# StarFive VisionFive 2 v1.2A register map
File version: 0.1
Registers are 32-bit, read-write, reset 0x0 unless marked. A register's access mark holds for its fields unless they carry their own. Offsets are from the block's base; [hi:lo] are bit positions; {n}, {i} and the like mark numbered series; 'fields as' and 'values as' point back to an identical list.

## stg_syscon — From starfive,jh7110-stg-syscon, peripheral generator
Base 0x10240000
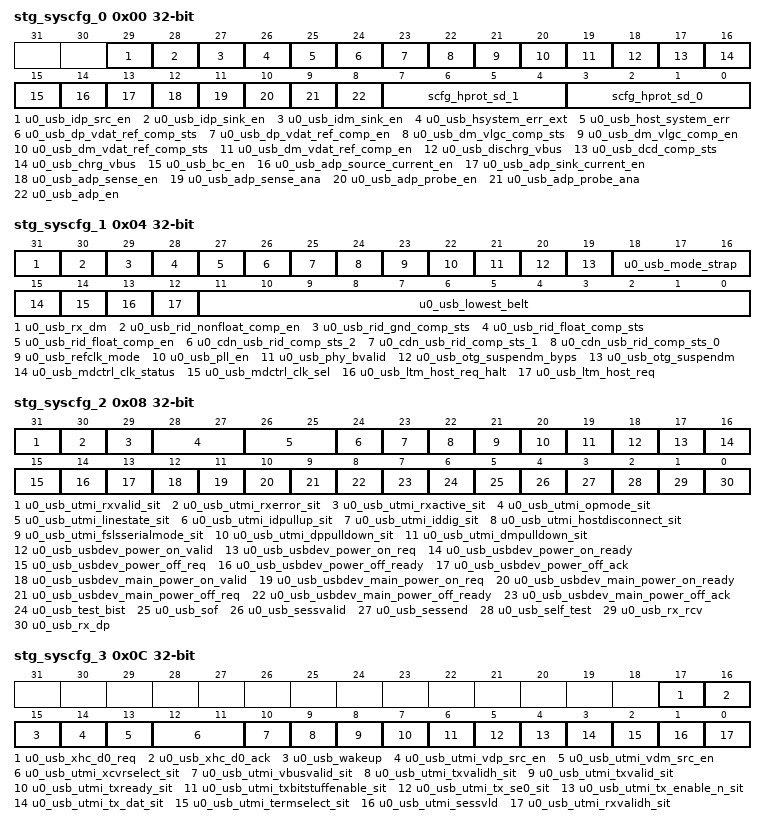
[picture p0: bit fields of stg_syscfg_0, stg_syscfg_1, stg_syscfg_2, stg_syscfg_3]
0x00 stg_syscfg_0 — STG SYCONSAIF SYSCFG 0
  [29] u0_usb_idp_src_en ro, [28] u0_usb_idp_sink_en ro, [27] u0_usb_idm_sink_en ro, [26] u0_usb_hsystem_err_ext ro, [25] u0_usb_host_system_err, [24] u0_usb_dp_vdat_ref_comp_sts, [23] u0_usb_dp_vdat_ref_comp_en ro, [22] u0_usb_dm_vlgc_comp_sts, [21] u0_usb_dm_vlgc_comp_en ro, [20] u0_usb_dm_vdat_ref_comp_sts, [19] u0_usb_dm_vdat_ref_comp_en ro, [18] u0_usb_dischrg_vbus, [17] u0_usb_dcd_comp_sts, [16] u0_usb_chrg_vbus, [15] u0_usb_bc_en ro, [14] u0_usb_adp_source_current_en ro, [13] u0_usb_adp_sink_current_en ro, [12] u0_usb_adp_sense_en ro, [11] u0_usb_adp_sense_ana, [10] u0_usb_adp_probe_en ro, [9] u0_usb_adp_probe_ana, [8] u0_usb_adp_en ro, [7:4] scfg_hprot_sd_1, [3:0] scfg_hprot_sd_0
0x04 stg_syscfg_1 — STG SYSCONSAIF SYSCFG 4
  [31] u0_usb_rx_dm ro
  [30] u0_usb_rid_nonfloat_comp_en ro
  [29] u0_usb_rid_gnd_comp_sts
  [28] u0_usb_rid_float_comp_sts
  [27] u0_usb_rid_float_comp_en ro
  [26] u0_cdn_usb_rid_comp_sts_2
  [25] u0_cdn_usb_rid_comp_sts_1
  [24] u0_cdn_usb_rid_comp_sts_0
  [23] u0_usb_refclk_mode
  [22] u0_usb_pll_en
  [21] u0_usb_phy_bvalid ro
  [20] u0_usb_otg_suspendm_byps
  [19] u0_usb_otg_suspendm
  [18:16] u0_usb_mode_strap — Can onlly be changed when pwrup_rst_n is low
  [15] u0_usb_mdctrl_clk_status ro
  [14] u0_usb_mdctrl_clk_sel
  [13] u0_usb_ltm_host_req_halt — LTM interface to software
  [12] u0_usb_ltm_host_req ro — LTM interface to software
  [11:0] u0_usb_lowest_belt ro — LTM interface to software
0x08 stg_syscfg_2 — STG SYSCONSAIF SYSCFG 8
  [31] u0_usb_utmi_rxvalid_sit ro
  [30] u0_usb_utmi_rxerror_sit ro
  [29] u0_usb_utmi_rxactive_sit ro
  [28:27] u0_usb_utmi_opmode_sit
  [26:25] u0_usb_utmi_linestate_sit ro
  [24] u0_usb_utmi_idpullup_sit
  [23] u0_usb_utmi_iddig_sit ro
  [22] u0_usb_utmi_hostdisconnect_sit ro
  [21] u0_usb_utmi_fslsserialmode_sit
  [20] u0_usb_utmi_dppulldown_sit
  [19] u0_usb_utmi_dmpulldown_sit
  [18] u0_usb_usbdev_power_on_valid
  [17] u0_usb_usbdev_power_on_req ro
  [16] u0_usb_usbdev_power_on_ready ro
  [15] u0_usb_usbdev_power_off_req
  [14] u0_usb_usbdev_power_off_ready ro
  [13] u0_usb_usbdev_power_off_ack ro
  [12] u0_usb_usbdev_main_power_on_valid
  [11] u0_usb_usbdev_main_power_on_req ro
  [10] u0_usb_usbdev_main_power_on_ready ro
  [9] u0_usb_usbdev_main_power_off_req
  [8] u0_usb_usbdev_main_power_off_ready ro
  [7] u0_usb_usbdev_main_power_off_ack ro
  [6] u0_usb_test_bist ro — For software bist_test
  [5] u0_usb_sof ro
  [4] u0_usb_sessvalid ro
  [3] u0_usb_sessend ro
  [2] u0_usb_self_test — For software bist_test
  [1] u0_usb_rx_rcv ro
  [0] u0_usb_rx_dp ro
0x0C stg_syscfg_3 — STG SYSCONSAIF SYSCFG 12
  [17] u0_usb_xhc_d0_req, [16] u0_usb_xhc_d0_ack ro, [15] u0_usb_wakeup, [14] u0_usb_utmi_vdp_src_en ro, [13] u0_usb_utmi_vdm_src_en ro, [12:11] u0_usb_utmi_xcvrselect_sit, [10] u0_usb_utmi_vbusvalid_sit ro, [9] u0_usb_utmi_txvalidh_sit, [8] u0_usb_utmi_txvalid_sit, [7] u0_usb_utmi_txready_sit ro, [6] u0_usb_utmi_txbitstuffenable_sit, [5] u0_usb_utmi_tx_se0_sit, [4] u0_usb_utmi_tx_enable_n_sit, [3] u0_usb_utmi_tx_dat_sit, [2] u0_usb_utmi_termselect_sit, [1] u0_usb_utmi_sessvld, [0] u0_usb_utmi_rxvalidh_sit ro
0x10 stg_syscfg_4 — STG SYSCONSAIF SYSCFG 16
  [31:0] u0_usb_xhci_debug_bus ro
0x14 stg_syscfg_5 — STG SYSCONSAIF SYSCFG 20
  [30:0] u0_usb_xhci_debug_link_state ro
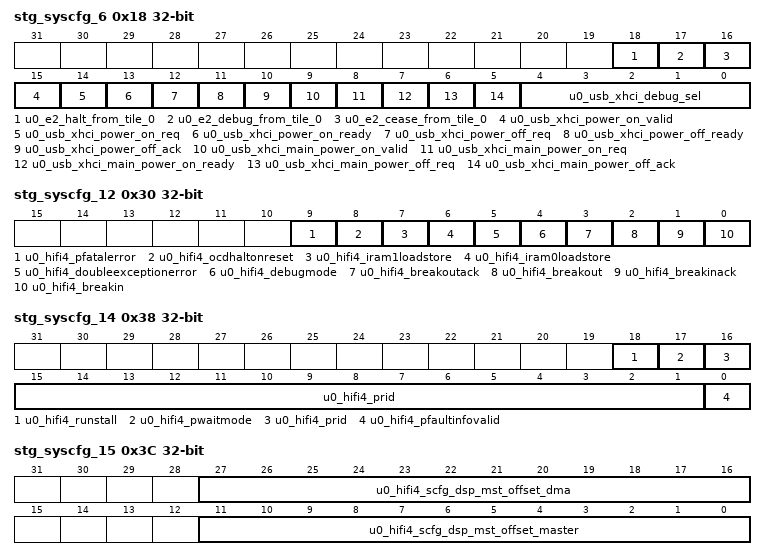
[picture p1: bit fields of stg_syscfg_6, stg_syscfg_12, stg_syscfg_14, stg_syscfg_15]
0x18 stg_syscfg_6 — STG SYSCONSAIF SYSCFG 24
  [18] u0_e2_halt_from_tile_0 ro, [17] u0_e2_debug_from_tile_0 ro, [16] u0_e2_cease_from_tile_0 ro, [15] u0_usb_xhci_power_on_valid, [14] u0_usb_xhci_power_on_req ro, [13] u0_usb_xhci_power_on_ready ro, [12] u0_usb_xhci_power_off_req, [11] u0_usb_xhci_power_off_ready ro, [10] u0_usb_xhci_power_off_ack ro, [9] u0_usb_xhci_main_power_on_valid, [8] u0_usb_xhci_main_power_on_req ro, [7] u0_usb_xhci_main_power_on_ready, [6] u0_usb_xhci_main_power_off_req ro, [5] u0_usb_xhci_main_power_off_ack ro, [4:0] u0_usb_xhci_debug_sel
0x1C stg_syscfg_7 — STG SYSCONSAIF SYSCFG 28
  [31:0] u0_e2_nmi_exception_vector
0x20 stg_syscfg_8 — STG SYSCONSAIF SYSCFG 32
  [31:0] u0_e2_nmi_interrupt_vector
0x24 stg_syscfg_9 — STG SYSCONSAIF SYSCFG 36
  [31:0] u0_e2_reset_vector_0
0x28 stg_syscfg_10 — STG SYSCONSAIF SYSCFG 40
  [0] u0_e2_wfi_from_tile_0 ro
0x2C stg_syscfg_11 — STG SYSCONSAIF SYSCFG 44
  [31:0] u0_hifi4_altresetvec — Reset Vector Address
0x30 stg_syscfg_12 — STG SYSCONSAIF SYSCFG 48
  [9] u0_hifi4_pfatalerror ro — Fault Handling Signals
  [8] u0_hifi4_ocdhaltonreset — Debug signal
  [7] u0_hifi4_iram1loadstore ro — Indicates that iram1 works
  [6] u0_hifi4_iram0loadstore ro — Indicates that iram0 works
  [5] u0_hifi4_doubleexceptionerror ro — Fault Handling Signals
  [4] u0_hifi4_debugmode ro — Debug signal
  [3] u0_hifi4_breakoutack — Debug signal
  [2] u0_hifi4_breakout ro — Debug signal
  [1] u0_hifi4_breakinack ro — Debug signal
  [0] u0_hifi4_breakin — Debug signal
0x34 stg_syscfg_13 — STG SYSCONSAIF SYSCFG 52
  [31:0] u0_hifi4_pfaultinfo ro — Fault Handling Signals
0x38 stg_syscfg_14 — STG SYSCONSAIF SYSCFG 56
  [18] u0_hifi4_runstall — Run Stall
  [17] u0_hifi4_pwaitmode ro — Wait Mode
  [16:1] u0_hifi4_prid — Module ID
  [0] u0_hifi4_pfaultinfovalid ro — Fault Handling Signals
0x3C stg_syscfg_15 — STG SYSCONSAIF SYSCFG 60
  [27:16] u0_hifi4_scfg_dsp_mst_offset_dma — Indicates the DMA port remap address
  [11:0] u0_hifi4_scfg_dsp_mst_offset_master — Indicates that master port remap address
0x40 stg_syscfg_16 — STG SYSCONSAIF SYSCFG 64
  [31:0] u0_hifi4_scfg_dsp_slv_offset — The value indicates the slave port remap address
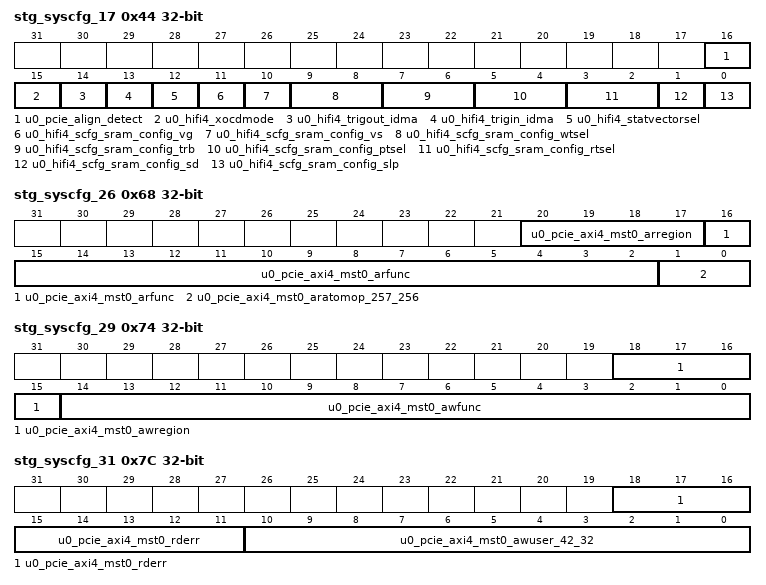
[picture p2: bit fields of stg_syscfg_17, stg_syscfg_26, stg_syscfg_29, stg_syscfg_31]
0x44 stg_syscfg_17 — STG SYSCONSAIF SYSCFG 68
  [16] u0_pcie_align_detect ro
  [15] u0_hifi4_xocdmode ro — Debug signal
  [14] u0_hifi4_trigout_idma ro — DMA port trigger
  [13] u0_hifi4_trigin_idma — DMA port trigger
  [12] u0_hifi4_statvectorsel — When the value is 1, it indicates that the AltResetVec is valid
  [11] u0_hifi4_scfg_sram_config_vg — SRAM/ROM configuration. VG: timing setting for debug purpose, default is 1'b1.
  [10] u0_hifi4_scfg_sram_config_vs — SRAM/ROM configuration. VS: timing setting for debug purpose, default is 1'b1.
  [9:8] u0_hifi4_scfg_sram_config_wtsel — SRAM/ROM configuration. WTSEL: timing setting for debug purpose, default is 2'b01.
  [7:6] u0_hifi4_scfg_sram_config_trb — SRAM/ROM configuration. TRB: timing setting for debug purpose, default is 2'b01.
  [5:4] u0_hifi4_scfg_sram_config_ptsel — SRAM/ROM configuration. PTSEL: timing setting for debug purpose, default is 2'b01.
  [3:2] u0_hifi4_scfg_sram_config_rtsel — SRAM/ROM configuration. RTSEL: timing setting for debug purpose, default is 2'b01.
  [1] u0_hifi4_scfg_sram_config_sd — SRAM/ROM configuration. SD: shutdown enable, high active, default is low.
  [0] u0_hifi4_scfg_sram_config_slp — SRAM/ROM configuration. SLP: sleep enable, high active, default is low.
{0x0+4i} stg_syscfg_{i} (i=18..25) — STG SYSCONSAIF SYSCFG {4i}
  [31:0] u0_pcie_axi4_mst0_aratomop_{32i-545}_{32i-576} ro
0x68 stg_syscfg_26 — STG SYSCONSAIF SYSCFG 104
  [20:17] u0_pcie_axi4_mst0_arregion ro, [16:2] u0_pcie_axi4_mst0_arfunc ro, [1:0] u0_pcie_axi4_mst0_aratomop_257_256 ro
0x6C stg_syscfg_27 — STG SYSCONSAIF SYSCFG 108
  [31:0] u0_pcie_axi4_mst0_aruser_31_0 ro
0x70 stg_syscfg_28 — STG SYSCONSAIF SYSCFG 112
  [31:0] u0_pcie_axi4_mst0_aruser_63_32 ro
0x74 stg_syscfg_29 — STG SYSCONSAIF SYSCFG 116
  [18:15] u0_pcie_axi4_mst0_awregion ro, [14:0] u0_pcie_axi4_mst0_awfunc ro
0x78 stg_syscfg_30 — STG SYSCONSAIF SYSCFG 120
  [31:0] u0_pcie_axi4_mst0_a2user_31_0 ro
0x7C stg_syscfg_31 — STG SYSCONSAIF SYSCFG 124
  [18:11] u0_pcie_axi4_mst0_rderr, [10:0] u0_pcie_axi4_mst0_awuser_42_32 ro
0x80 stg_syscfg_32 — STG SYSCONSAIF SYSCFG 128
  [31:0] u0_pcie_axi4_mst0_ruser
0x84 stg_syscfg_33 — STG SYSCONSAIF SYSCFG 132
  [7:0] u0_pcie_axi4_mst0_wderr ro
{0x0+4i} stg_syscfg_{i} (i=34..41) — STG SYSCONSAIF SYSCFG {4i}
  [31:0] u0_pcie_axi4_slv0_aratomop_{32i-1057}_{32i-1088}
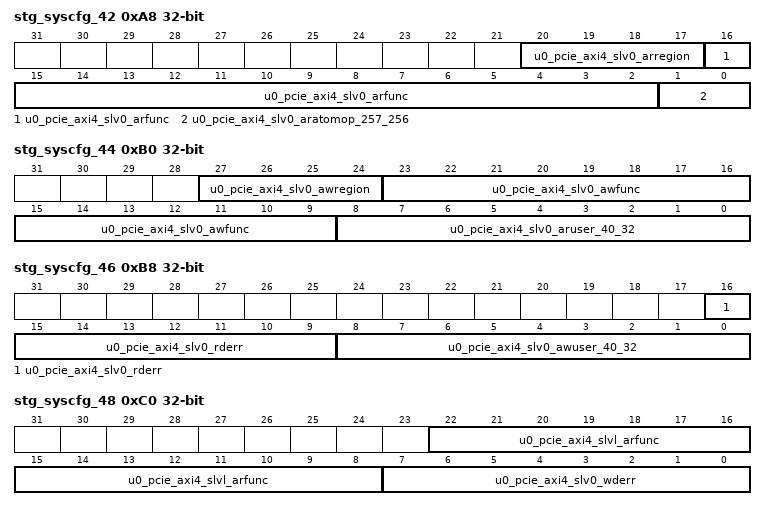
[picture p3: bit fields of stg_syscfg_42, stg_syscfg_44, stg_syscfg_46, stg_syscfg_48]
0xA8 stg_syscfg_42 — STG SYSCONSAIF SYSCFG 168
  [20:17] u0_pcie_axi4_slv0_arregion, [16:2] u0_pcie_axi4_slv0_arfunc, [1:0] u0_pcie_axi4_slv0_aratomop_257_256
0xAC stg_syscfg_43 — STG SYSCONSAIF SYSCFG 172
  [31:0] u0_pcie_axi4_slv0_aruser_31_0
0xB0 stg_syscfg_44 — STG SYSCONSAIF SYSCFG 176
  [27:24] u0_pcie_axi4_slv0_awregion, [23:9] u0_pcie_axi4_slv0_awfunc, [8:0] u0_pcie_axi4_slv0_aruser_40_32
0xB4 stg_syscfg_45 — STG SYSCONSAIF SYSCFG 180
  [31:0] u0_pcie_axi4_slv0_awuser_31_0
0xB8 stg_syscfg_46 — STG SYSCONSAIF SYSCFG 184
  [16:9] u0_pcie_axi4_slv0_rderr ro, [8:0] u0_pcie_axi4_slv0_awuser_40_32
0xBC stg_syscfg_47 — STG SYSCONSAIF SYSCFG 188
  [31:0] u0_pcie_axi4_slv0_ruser ro
0xC0 stg_syscfg_48 — STG SYSCONSAIF SYSCFG 192
  [22:8] u0_pcie_axi4_slvl_arfunc ro, [7:0] u0_pcie_axi4_slv0_wderr
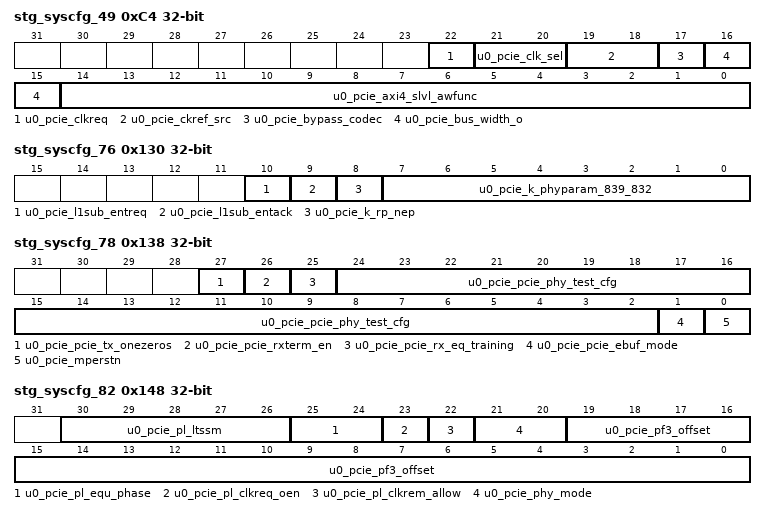
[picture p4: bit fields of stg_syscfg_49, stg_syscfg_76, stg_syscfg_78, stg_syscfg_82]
0xC4 stg_syscfg_49 — STG SYSCONSAIF SYSCFG 196
  [22] u0_pcie_clkreq, [21:20] u0_pcie_clk_sel, [19:18] u0_pcie_ckref_src, [17] u0_pcie_bypass_codec, [16:15] u0_pcie_bus_width_o ro, [14:0] u0_pcie_axi4_slvl_awfunc
{0x0+4i} stg_syscfg_{i} (i=50..75) — STG SYSCONSAIF SYSCFG {4i}
  [31:0] u0_pcie_k_phyparam_{32i-1569}_{32i-1600}
0x130 stg_syscfg_76 — STG SYSCONSAIF SYSCFG 304
  [10] u0_pcie_l1sub_entreq, [9] u0_pcie_l1sub_entack ro, [8] u0_pcie_k_rp_nep, [7:0] u0_pcie_k_phyparam_839_832
0x134 stg_syscfg_77 — STG SYSCONSAIF SYSCFG 308
  [31:0] u0_pcie_local_interrupt_in
0x138 stg_syscfg_78 — STG SYSCONSAIF SYSCFG 312
  [27] u0_pcie_pcie_tx_onezeros, [26] u0_pcie_pcie_rxterm_en, [25] u0_pcie_pcie_rx_eq_training, [24:2] u0_pcie_pcie_phy_test_cfg, [1] u0_pcie_pcie_ebuf_mode, [0] u0_pcie_mperstn
{0x0+4i} stg_syscfg_{i} (i=79..81) — STG SYSCONSAIF SYSCFG {4i}
  [19:0] u0_pcie_pf{i-79}_offset
0x148 stg_syscfg_82 — STG SYSCONSAIF SYSCFG 328
  [30:26] u0_pcie_pl_ltssm ro, [25:24] u0_pcie_pl_equ_phase ro, [23] u0_pcie_pl_clkreq_oen ro, [22] u0_pcie_pl_clkrem_allow, [21:20] u0_pcie_phy_mode, [19:0] u0_pcie_pf3_offset
0x14C stg_syscfg_83 — STG SYSCONSAIF SYSCFG 332
  [4:0] u0_pcie_pl_pclk_rate ro
0x150 stg_syscfg_84 — STG SYSCONSAIF SYSCFG 336
  [31:0] u0_pcie_pl_sideband_in_31_0 ro
0x154 stg_syscfg_85 — STG SYSCONSAIF SYSCFG 340
  [31:0] u0_pcie_pl_sideband_in_63_32 ro
0x158 stg_syscfg_86 — STG SYSCONSAIF SYSCFG 344
  [31:0] u0_pcie_pl_sideband_out_31_0 ro
0x15C stg_syscfg_87 — STG SYSCONSAIF SYSCFG 348
  [31:0] u0_pcie_pl_sideband_out_63_32 ro
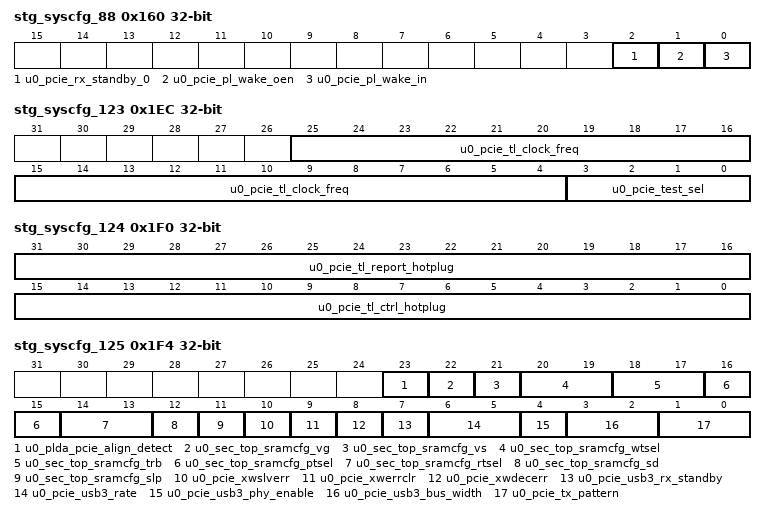
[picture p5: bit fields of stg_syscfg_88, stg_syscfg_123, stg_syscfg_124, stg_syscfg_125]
0x160 stg_syscfg_88 — STG SYSCONSAIF SYSCFG 352
  [2] u0_pcie_rx_standby_0 ro, [1] u0_pcie_pl_wake_oen ro, [0] u0_pcie_pl_wake_in
0x164 stg_syscfg_89 — STG SYSCONSAIF SYSCFG 356
  [31:0] u0_pcie_test_in_31_0
0x168 stg_syscfg_90 — STG SYSCONSAIF SYSCFG 360
  [31:0] u0_pcie_test_in_63_32
{0x0+4i} stg_syscfg_{i} (i=91..106) — STG SYSCONSAIF SYSCFG {4i}
  [31:0] u0_pcie_test_out_bridge_{32i-2881}_{32i-2912} ro
{0x0+4i} stg_syscfg_{i} (i=107..122) — STG SYSCONSAIF SYSCFG {4i}
  [31:0] u0_pcie_test_out_pcie_{32i-3393}_{32i-3424} ro
0x1EC stg_syscfg_123 — STG SYSCONSAIF SYSCFG 492
  [25:4] u0_pcie_tl_clock_freq, [3:0] u0_pcie_test_sel
0x1F0 stg_syscfg_124 — STG SYSCONSAIF SYSCFG 496
  [31:16] u0_pcie_tl_report_hotplug, [15:0] u0_pcie_tl_ctrl_hotplug ro
0x1F4 stg_syscfg_125 — STG SYSCONSAIF SYSCFG 500
  [23] u0_plda_pcie_align_detect ro
  [22] u0_sec_top_sramcfg_vg — SRAM/ROM configuration. VG: timing setting for debug purpose, default is 1'b1.
  [21] u0_sec_top_sramcfg_vs — SRAM/ROM configuration. VS: timing setting for debug purpose, default is 1'b1.
  [20:19] u0_sec_top_sramcfg_wtsel — SRAM/ROM configuration. WTSEL: timing setting for debug purpose, default is 2'b01.
  [18:17] u0_sec_top_sramcfg_trb — SRAM/ROM configuration. TRB: timing setting for debug purpose, default is 2'b01.
  [16:15] u0_sec_top_sramcfg_ptsel — SRAM/ROM configuration. PTSEL: timing setting for debug purpose, default is 2'b01.
  [14:13] u0_sec_top_sramcfg_rtsel — SRAM/ROM configuration. RTSEL: timing setting for debug purpose, default is 2'b01.
  [12] u0_sec_top_sramcfg_sd — SRAM/ROM configuration. SD: shutdown enable, high active, default is low.
  [11] u0_sec_top_sramcfg_slp — SRAM/ROM configuration. SLP: sleep enable, high active, default is low.
  [10] u0_pcie_xwslverr ro
  [9] u0_pcie_xwerrclr
  [8] u0_pcie_xwdecerr ro
  [7] u0_pcie_usb3_rx_standby
  [6:5] u0_pcie_usb3_rate
  [4] u0_pcie_usb3_phy_enable
  [3:2] u0_pcie_usb3_bus_width
  [1:0] u0_pcie_tx_pattern
{0x0+4i} stg_syscfg_{i} (i=126..133) — STG SYSCONSAIF SYSCFG {4i}
  [31:0] u0_pcie_axi4_mst0_aratomop_{32i-4001}_{32i-4032} ro
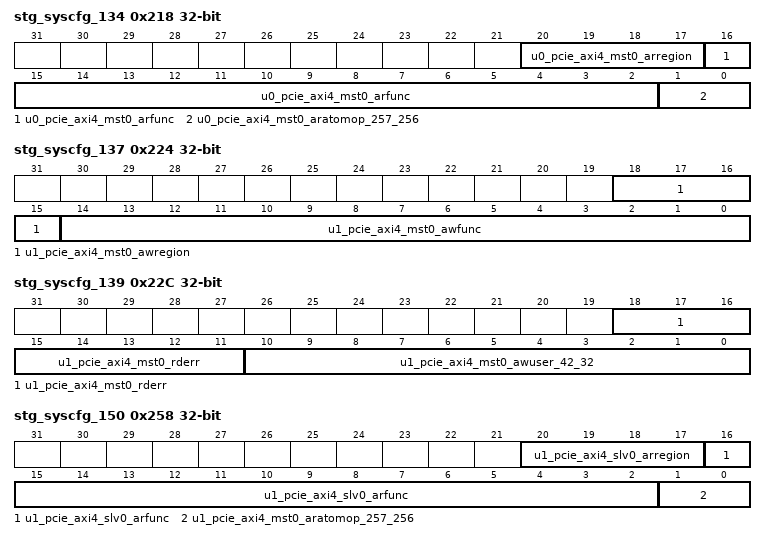
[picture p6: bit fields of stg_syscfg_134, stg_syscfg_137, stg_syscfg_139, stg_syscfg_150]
0x218 stg_syscfg_134 — STG SYSCONSAIF SYSCFG 536
  fields as stg_syscfg_26
0x21C stg_syscfg_135 — STG SYSCONSAIF SYSCFG 540
  [31:0] u1_pcie_axi4_mst0_aruser_31_0 ro
0x220 stg_syscfg_136 — STG SYSCONSAIF SYSCFG 544
  [20:0] u1_pcie_axi4_mst0_aruser_52_32 ro
0x224 stg_syscfg_137 — STG SYSCONSAIF SYSCFG 548
  [18:15] u1_pcie_axi4_mst0_awregion ro, [14:0] u1_pcie_axi4_mst0_awfunc ro
0x228 stg_syscfg_138 — STG SYSCONSAIF SYSCFG 552
  [31:0] u1_pcie_axi4_mst0_awuser_31_0 ro
0x22C stg_syscfg_139 — STG SYSCONSAIF SYSCFG 556
  [18:11] u1_pcie_axi4_mst0_rderr, [10:0] u1_pcie_axi4_mst0_awuser_42_32 ro
0x230 stg_syscfg_140 — STG SYSCONSAIF SYSCFG 560
  [31:0] u1_pcie_axi4_mst0_ruser
0x234 stg_syscfg_141 — STG SYSCONSAIF SYSCFG 564
  [7:0] u1_pcie_axi4_mst0_wderr ro
{0x0+4i} stg_syscfg_{i} (i=142..149) — STG SYSCONSAIF SYSCFG {4i}
  [31:0] u1_pcie_axi4_slv0_aratomop_{32i-4513}_{32i-4544}
0x258 stg_syscfg_150 — STG SYSCONSAIF SYSCFG 600
  [20:17] u1_pcie_axi4_slv0_arregion, [16:2] u1_pcie_axi4_slv0_arfunc, [1:0] u1_pcie_axi4_mst0_aratomop_257_256
0x25C stg_syscfg_151 — STG SYSCONSAIF SYSCFG 604
  [31:0] u1_pcie_axi4_slv0_aruser_31_0
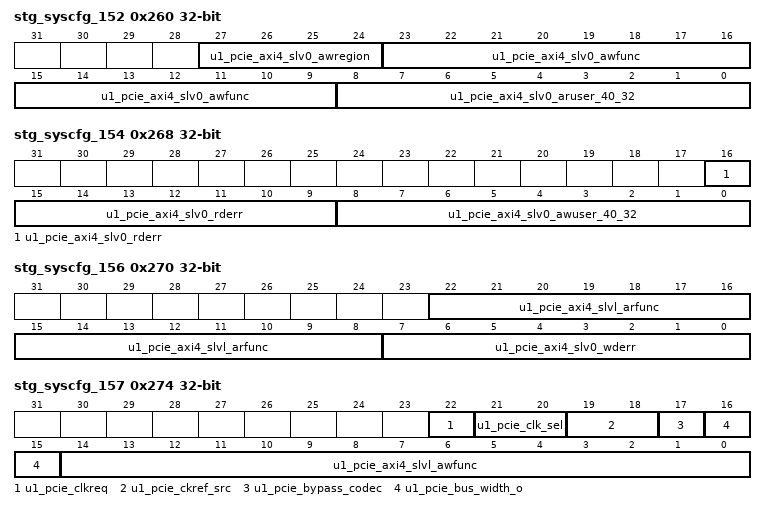
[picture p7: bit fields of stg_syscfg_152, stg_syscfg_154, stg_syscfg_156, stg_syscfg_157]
0x260 stg_syscfg_152 — STG SYSCONSAIF SYSCFG 608
  [27:24] u1_pcie_axi4_slv0_awregion, [23:9] u1_pcie_axi4_slv0_awfunc, [8:0] u1_pcie_axi4_slv0_aruser_40_32
0x264 stg_syscfg_153 — STG SYSCONSAIF SYSCFG 612
  [31:0] u1_pcie_axi4_slv0_awuser_31_0
0x268 stg_syscfg_154 — STG SYSCONSAIF SYSCFG 616
  [16:9] u1_pcie_axi4_slv0_rderr ro, [8:0] u1_pcie_axi4_slv0_awuser_40_32
0x26C stg_syscfg_155 — STG SYSCONSAIF SYSCFG 620
  [31:0] u1_pcie_axi4_slv0_ruser ro
0x270 stg_syscfg_156 — STG SYSCONSAIF SYSCFG 624
  [22:8] u1_pcie_axi4_slvl_arfunc, [7:0] u1_pcie_axi4_slv0_wderr
0x274 stg_syscfg_157 — STG SYSCONSAIF SYSCFG 628
  [22] u1_pcie_clkreq, [21:20] u1_pcie_clk_sel, [19:18] u1_pcie_ckref_src, [17] u1_pcie_bypass_codec, [16:15] u1_pcie_bus_width_o ro, [14:0] u1_pcie_axi4_slvl_awfunc
{0x0+4i} stg_syscfg_{i} (i=158..183) — STG SYSCONSAIF SYSCFG {4i}
  [31:0] u1_plda_pcie_k_phyparam_{32i-5025}_{32i-5056}
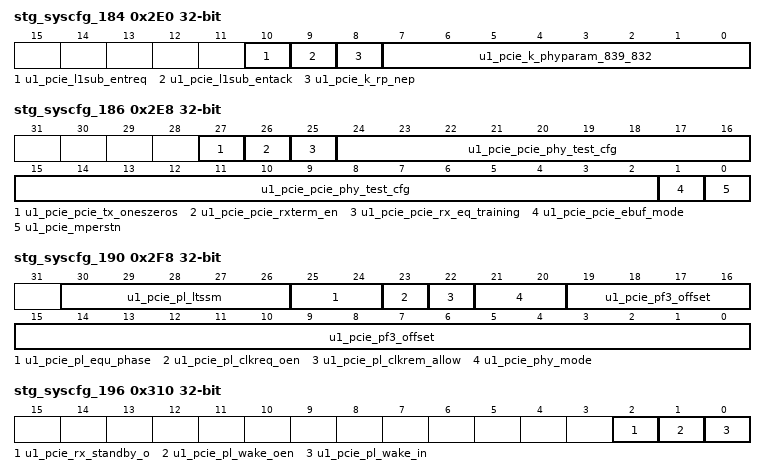
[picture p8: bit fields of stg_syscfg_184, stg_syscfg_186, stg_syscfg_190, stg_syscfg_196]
0x2E0 stg_syscfg_184 — STG SYSCONSAIF SYSCFG 736
  [10] u1_pcie_l1sub_entreq, [9] u1_pcie_l1sub_entack ro, [8] u1_pcie_k_rp_nep, [7:0] u1_pcie_k_phyparam_839_832
0x2E4 stg_syscfg_185 — STG SYSCONSAIF SYSCFG 740
  [31:0] u1_pcie_local_interrupt_in
0x2E8 stg_syscfg_186 — STG SYSCONSAIF SYSCFG 744
  [27] u1_pcie_pcie_tx_oneszeros, [26] u1_pcie_pcie_rxterm_en, [25] u1_pcie_pcie_rx_eq_training, [24:2] u1_pcie_pcie_phy_test_cfg, [1] u1_pcie_pcie_ebuf_mode, [0] u1_pcie_mperstn
{0x0+4i} stg_syscfg_{i} (i=187..189) — STG SYSCONSAIF SYSCFG {4i}
  [19:0] u1_pcie_pf{i-187}_offset
0x2F8 stg_syscfg_190 — STG SYSCONSAIF SYSCFG 760
  [30:26] u1_pcie_pl_ltssm ro, [25:24] u1_pcie_pl_equ_phase ro, [23] u1_pcie_pl_clkreq_oen ro, [22] u1_pcie_pl_clkrem_allow, [21:20] u1_pcie_phy_mode, [19:0] u1_pcie_pf3_offset
0x2FC stg_syscfg_191 — STG SYSCONSAIF SYSCFG 764
  [4:0] u1_pcie_pl_pclk_rate ro
0x300 stg_syscfg_192 — STG SYSCONSAIF SYSCFG 768
  [31:0] u1_pcie_pl_sideband_in_31_0
0x304 stg_syscfg_193 — STG SYSCONSAIF SYSCFG 772
  [31:0] u1_pcie_pl_sideband_in_63_32
0x308 stg_syscfg_194 — STG SYSCONSAIF SYSCFG 776
  [31:0] u1_pcie_pl_sideband_out_31_0
0x30C stg_syscfg_195 — STG SYSCONSAIF SYSCFG 780
  [31:0] u1_pcie_pl_sideband_out_63_32
0x310 stg_syscfg_196 — STG SYSCONSAIF SYSCFG 784
  [2] u1_pcie_rx_standby_o ro, [1] u1_pcie_pl_wake_oen ro, [0] u1_pcie_pl_wake_in
0x314 stg_syscfg_197 — STG SYSCONSAIF SYSCFG 788
  [31:0] u1_pcie_test_in_31_0
0x318 stg_syscfg_198 — STG SYSCONSAIF SYSCFG 792
  [31:0] u1_pcie_test_in_63_32
{0x0+4i} stg_syscfg_{i} (i=199..214) — STG SYSCONSAIF SYSCFG {4i}
  [31:0] u1_pcie_test_out_bridge_{32i-6337}_{32i-6368}
{0x0+4i} stg_syscfg_{i} (i=215..230) — STG SYSCONSAIF SYSCFG {4i}
  [31:0] u1_pcie_test_out_pcie_{32i-6849}_{32i-6880} ro
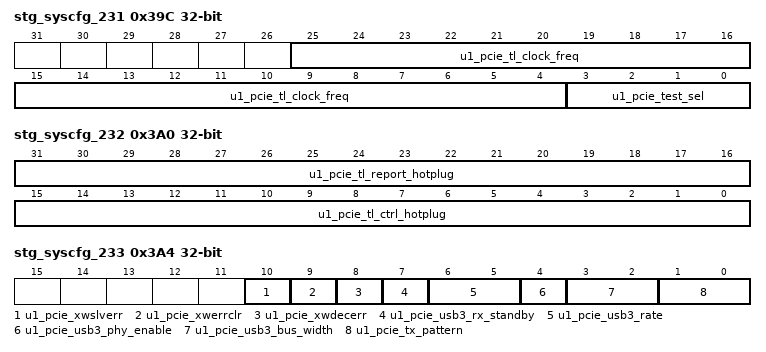
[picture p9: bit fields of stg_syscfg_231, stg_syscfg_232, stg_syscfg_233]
0x39C stg_syscfg_231 — STG SYSCONSAIF SYSCFG 924
  [25:4] u1_pcie_tl_clock_freq, [3:0] u1_pcie_test_sel
0x3A0 stg_syscfg_232 — STG SYSCONSAIF SYSCFG 928
  [31:16] u1_pcie_tl_report_hotplug, [15:0] u1_pcie_tl_ctrl_hotplug ro
0x3A4 stg_syscfg_233 — STG SYSCONSAIF SYSCFG 932
  [10] u1_pcie_xwslverr ro, [9] u1_pcie_xwerrclr, [8] u1_pcie_xwdecerr ro, [7] u1_pcie_usb3_rx_standby, [6:5] u1_pcie_usb3_rate, [4] u1_pcie_usb3_phy_enable, [3:2] u1_pcie_usb3_bus_width, [1:0] u1_pcie_tx_pattern
